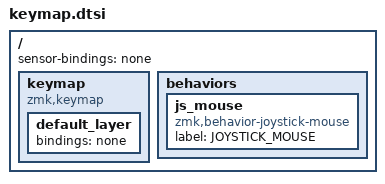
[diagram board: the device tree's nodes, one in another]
/dts-v1/;
/plugin/;

#include <dt-bindings/zmk/keys.h>
#include <behaviors.dtsi>

/ {
	keymap {
		compatible = "zmk,keymap";
		
		// 只有一个层，没有实际按键
		default_layer {
			bindings = <
				&none  // 虚拟按键，不执行任何操作
			>;
		};
	};
	
	// 摇杆行为定义
	behaviors {
		js_mouse: js_mouse {
			compatible = "zmk,behavior-joystick-mouse";
			label = "JOYSTICK_MOUSE";
			#binding-cells = <0>;
		};
	};
	
	// 虚拟按键绑定（确保键盘扫描正常工作）
	sensor-bindings = <&none>;
};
